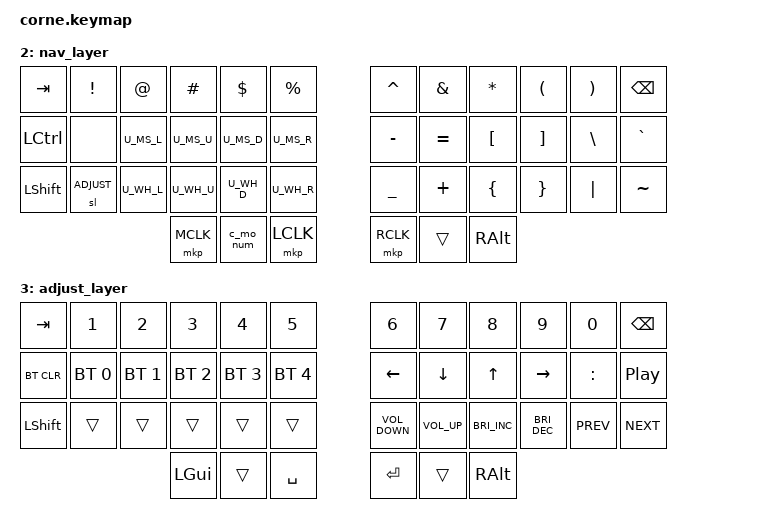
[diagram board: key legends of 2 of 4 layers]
/*
 * Copyright (c) 2020 The ZMK Contributors
 *
 * SPDX-License-Identifier: MIT
 */

#include <behaviors.dtsi>
#include <dt-bindings/zmk/keys.h>
#include <dt-bindings/zmk/bt.h>
#include <dt-bindings/zmk/outputs.h>
#include <dt-bindings/zmk/ext_power.h>
#include "keypos_42keys.h"
#include "mouse.dtsi"
#include <dt-bindings/zmk/mouse.h>


// Define Home row mods
#define C_HM_L(k1, k2, k3, k4) &c_hm_l LSHFT k1  &c_hm_l LGUI k2  &c_hm_l LALT k3  &c_hm_l LCTRL k4
#define C_HM_R(k1, k2, k3, k4) &c_hm_r RCTRL k1  &c_hm_r RALT k2  &c_hm_r RGUI k3  &c_hm_r RSHFT k4
#define C_LT(l1, k1) &c_lt l1 k1

// divide keys in 2 halfs ( see keypod_42keys.h for key locations)
#define KEYS_L LT4 LT3 LT2 LT1 LT0 LM4 LM3 LM2 LM1 LM0 LB4 LB3 LB2 LB1 LB0 // left-hand keys
#define KEYS_R RT0 RT1 RT2 RT3 RT4 RM0 RM1 RM2 RM3 RM4 RB0 RB1 RB2 RB3 RB4 // right-hand keys
#define KEYS_T LH2 LH1 LH0 RH0 RH1 RH2 // thumb keys

// define layers
#define QUERTY 0
#define NUM 1
#define NAV 2
#define ADJUST 3

// define much used keys
#define ______ &trans
#define xxxxxx &none


/ {

    behaviors {
        c_hm_l: homerow_left_mod {
            compatible = "zmk,behavior-hold-tap";
            quick-tap-ms = <150>; // tap held if same key is pressed twice within that time
            tapping-term-ms = <275>;
            require-prior-idle-ms = <150>; // tap if prev non modifier key was pressed within that time
            flavor = "balanced"; // hold if another key is both pressed and released within the tapping term
            #binding-cells = <2>;
            bindings = <&kp>, <&kp>;
            hold-trigger-key-positions = <KEYS_R KEYS_T>;
            hold-trigger-on-release; // delay positional check until key-release
        };

        c_hm_r: homerow_right_mod {
            compatible = "zmk,behavior-hold-tap";
            quick-tap-ms = <150>; // tap held if same key is pressed twice within that time
            tapping-term-ms = <275>;
            require-prior-idle-ms = <150>; // tap if prev non modifier key was pressed within that time
            flavor = "balanced"; // hold if another key is both pressed and released within the tapping term
            #binding-cells = <2>;
            bindings = <&kp>, <&kp>;
            hold-trigger-key-positions = <KEYS_L KEYS_T>;
            hold-trigger-on-release; // delay positional check until key-release
        };

        c_lt: layer_tab {
            compatible = "zmk,behavior-hold-tap";
            quick-tap-ms = <150>; // tap held if same key is pressed twice within that time
            tapping-term-ms = <125>; // tap if key was pressed within that time
            flavor = "hold-preferred";
            #binding-cells = <2>;
            bindings = <&mo>, <&kp>;
        };
    };

    keymap {
        compatible = "zmk,keymap";
        qwerty_layer {
            bindings = <
&kp ESCAPE            &kp Q      &kp W  &kp E     &kp R           &kp T		       &kp Y    &kp U      &kp I      &kp O    &kp P     &kp BSPC
&mt LEFT_CONTROL TAB  C_HM_L(A,      S,     D,        F)          &kp G		       &kp H    C_HM_R(J,      K,         L,       SEMI) &kp SQT
&kp LSHFT             &kp Z      &kp X  &kp C     &kp V           &kp B		       &kp N    &kp M      &kp COMMA  &kp DOT  &kp FSLH  &kp RIGHT_CONTROL
			         &kp LSHFT        C_LT(NUM, TAB)  &kp SPACE	       &kp RET C_LT(NAV, ESCAPE) &kp RSHFT
            >;
        };

        num_layer {
            bindings = <
&kp TAB               &kp N1       &kp N2    &kp N3    &kp N4    &kp N5		&kp N6     &kp N7            &kp N8    &kp N9        &kp N0    &kp BSPC
&mt LEFT_CONTROL TAB  C_HM_L(EXCL, DLLR,         LPAR,     RPAR) xxxxxx		&kp LEFT   C_HM_R(DOWN,      UP,       RIGHT,       COLON)     ______
&kp LSHFT             &kp MINUS    &kp EQUAL &kp LBKT  &kp RBKT  &kp BSLH	&kp UNDER  &kp PLUS          &kp LBRC  &kp RBRC     &kp PIPE   &kp TILDE
                                             &kp LGUI  ______    &kp SPACE	&kp RET   ______            &kp RSHFT
            >;
        };

        nav_layer {
            bindings = <
&kp TAB    &kp EXCL   &kp AT  &kp HASH  &kp DLLR  &kp PRCNT	      &kp CARET  &kp AMPS   &kp ASTRK  &kp LPAR  &kp RPAR  &kp BSPC
&kp LCTRL  xxxxxx     U_MS_L  U_MS_U    U_MS_D    U_MS_R	      &kp MINUS  &kp EQUAL  &kp LBKT   &kp RBKT  &kp BSLH  &kp GRAVE
&kp LSHFT  &sl ADJUST U_WH_L  U_WH_U    U_WH_D    U_WH_R  	      &kp UNDER  &kp PLUS   &kp LBRC   &kp RBRC  &kp PIPE  &kp TILDE
                              &mkp MCLK &c_mo_num &mkp LCLK	      &mkp RCLK  ______     &kp RALT
            >;
        };

	adjust_layer {
            bindings = <
&kp TAB     &kp N1        &kp N2        &kp N3        &kp N4        &kp N5		    &kp N6             &kp N7           &kp N8                &kp N9                &kp N0      &kp BSPC
&bt BT_CLR  &bt BT_SEL 0  &bt BT_SEL 1  &bt BT_SEL 2  &bt BT_SEL 3  &bt BT_SEL 4            &kp LEFT           &kp DOWN         &kp UP                &kp RIGHT             &kp COLON   &kp C_PLAY_PAUSE
&kp LSHFT   ______        ______        ______        ______        ______                  &kp C_VOLUME_DOWN  &kp C_VOLUME_UP  &kp C_BRIGHTNESS_INC  &kp C_BRIGHTNESS_DEC  &kp C_PREV  &kp C_NEXT
                                        &kp LGUI      ______        &kp SPACE		    &kp RET            ______           &kp RALT
	    >;		
	};
    };


    // docs: https://zmk.dev/docs/behaviors/macros
    macros {
        c_mo_num: momentary_layer_num {
            compatible = "zmk,behavior-macro";
            #binding-cells = <0>;
            wait-ms = <1>;
            bindings
                = <&macro_release &mo NAV>
                , <&macro_press &mo NUM>
                , <&macro_pause_for_release>
                , <&macro_release &mo NUM>
                ;
        };
    };

    // docs: https://zmk.dev/docs/keymaps/combos
    combos {
      compatible = "zmk,combos";
      cut {
        timeout-ms = <18>;
        bindings = <&kp LC(X)>;
        key-positions = <LB3 LB1>;
        layers = <QUERTY>;
        require-prior-idle-ms = <150>;
      };
      copy {
        timeout-ms = <18>;
        bindings = <&kp LC(INS)>;
        key-positions = <LB3 LB2>;
        layers = <QUERTY>;
        require-prior-idle-ms = <150>;
      };
      paste {
        timeout-ms = <18>;
        bindings = <&kp LS(INS)>;
        key-positions = <LB2 LB1>;
        layers = <QUERTY>;
        require-prior-idle-ms = <150>;
      };
      selall {
        timeout-ms = <18>;
        bindings = <&kp LC(A)>;
        key-positions = <LT3 LT2>;
        layers = <QUERTY>;
        require-prior-idle-ms = <150>;
      };
    };
};

// vim: filetype=c
// vim: syntax=off
